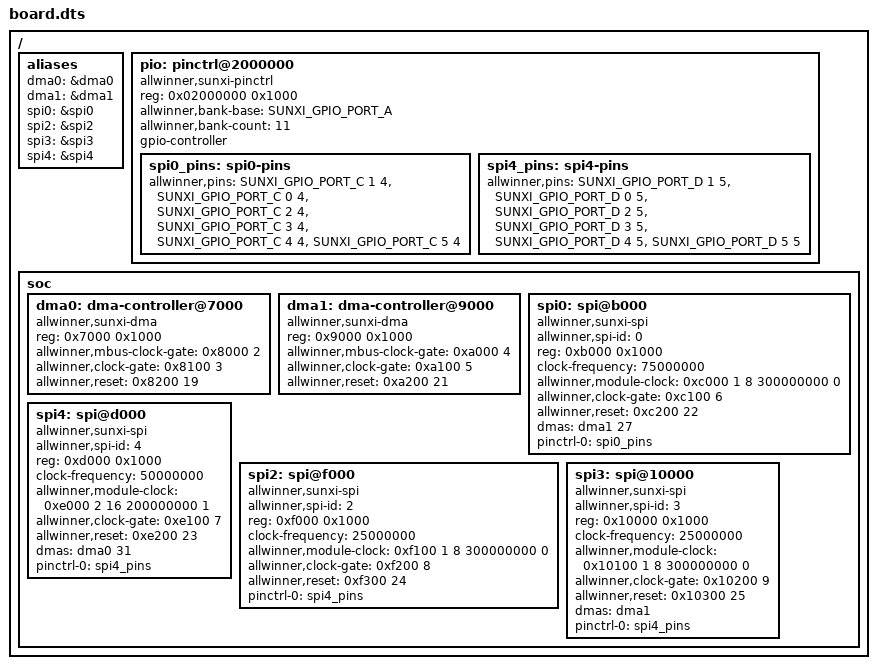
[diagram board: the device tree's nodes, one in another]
/dts-v1/;

#include <dt-bindings/gpio/sunxi-gpio.h>

/ {
	#address-cells = <1>;
	#size-cells = <1>;

	aliases {
		dma0 = &dma0;
		dma1 = &dma1;
		spi0 = &spi0;
		spi2 = &spi2;
		spi3 = &spi3;
		spi4 = &spi4;
	};

	pio: pinctrl@2000000 {
		compatible = "allwinner,sunxi-pinctrl";
		reg = <0x02000000 0x1000>;
		allwinner,bank-base = <SUNXI_GPIO_PORT_A>;
		allwinner,bank-count = <11>;
		#gpio-cells = <3>;
		gpio-controller;

		spi0_pins: spi0-pins {
			allwinner,pins =
				<SUNXI_GPIO_PORT_C 1 4>,
				<SUNXI_GPIO_PORT_C 0 4>,
				<SUNXI_GPIO_PORT_C 2 4>,
				<SUNXI_GPIO_PORT_C 3 4>,
				<SUNXI_GPIO_PORT_C 4 4>,
				<SUNXI_GPIO_PORT_C 5 4>;
		};

		spi4_pins: spi4-pins {
			allwinner,pins =
				<SUNXI_GPIO_PORT_D 1 5>,
				<SUNXI_GPIO_PORT_D 0 5>,
				<SUNXI_GPIO_PORT_D 2 5>,
				<SUNXI_GPIO_PORT_D 3 5>,
				<SUNXI_GPIO_PORT_D 4 5>,
				<SUNXI_GPIO_PORT_D 5 5>;
		};
	};

	soc {
		#address-cells = <1>;
		#size-cells = <1>;
		ranges;

		dma0: dma-controller@7000 {
			compatible = "allwinner,sunxi-dma";
			reg = <0x7000 0x1000>;
			#dma-cells = <1>;
			allwinner,mbus-clock-gate = <0x8000 2>;
			allwinner,clock-gate = <0x8100 3>;
			allwinner,reset = <0x8200 19>;
			status = "okay";
		};

		dma1: dma-controller@9000 {
			compatible = "allwinner,sunxi-dma";
			reg = <0x9000 0x1000>;
			#dma-cells = <1>;
			allwinner,mbus-clock-gate = <0xa000 4>;
			allwinner,clock-gate = <0xa100 5>;
			allwinner,reset = <0xa200 21>;
			status = "okay";
		};

		spi0: spi@b000 {
			compatible = "allwinner,sunxi-spi";
			allwinner,spi-id = <0>;
			reg = <0xb000 0x1000>;
			clock-frequency = <75000000>;
			allwinner,module-clock = <0xc000 1 8 300000000 0>;
			allwinner,clock-gate = <0xc100 6>;
			allwinner,reset = <0xc200 22>;
			dmas = <&dma1 27>;
			dma-names = "rx";
			pinctrl-names = "default";
			pinctrl-0 = <&spi0_pins>;
			status = "okay";
		};

		spi4: spi@d000 {
			compatible = "allwinner,sunxi-spi";
			allwinner,spi-id = <4>;
			reg = <0xd000 0x1000>;
			clock-frequency = <50000000>;
			allwinner,module-clock = <0xe000 2 16 200000000 1>;
			allwinner,clock-gate = <0xe100 7>;
			allwinner,reset = <0xe200 23>;
			dmas = <&dma0 31>;
			dma-names = "rx";
			pinctrl-names = "default";
			pinctrl-0 = <&spi4_pins>;
			status = "okay";
		};

		spi2: spi@f000 {
			compatible = "allwinner,sunxi-spi";
			allwinner,spi-id = <2>;
			reg = <0xf000 0x1000>;
			clock-frequency = <25000000>;
			allwinner,module-clock = <0xf100 1 8 300000000 0>;
			allwinner,clock-gate = <0xf200 8>;
			allwinner,reset = <0xf300 24>;
			pinctrl-names = "default";
			pinctrl-0 = <&spi4_pins>;
			status = "okay";
		};

		spi3: spi@10000 {
			compatible = "allwinner,sunxi-spi";
			allwinner,spi-id = <3>;
			reg = <0x10000 0x1000>;
			clock-frequency = <25000000>;
			allwinner,module-clock = <0x10100 1 8 300000000 0>;
			allwinner,clock-gate = <0x10200 9>;
			allwinner,reset = <0x10300 25>;
			dmas = <&dma1>;
			dma-names = "rx";
			pinctrl-names = "default";
			pinctrl-0 = <&spi4_pins>;
			status = "okay";
		};
	};
};
